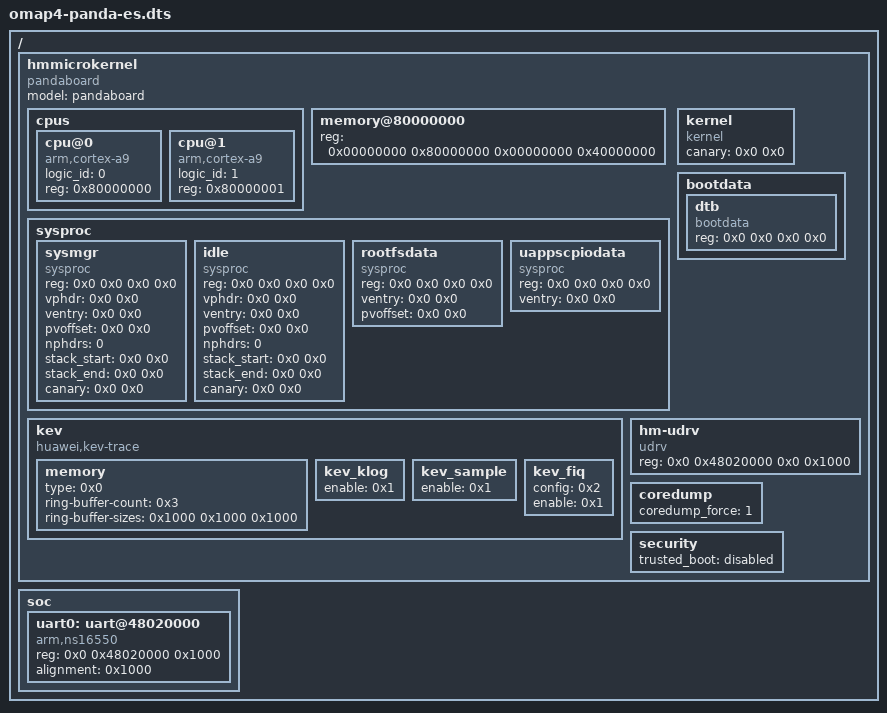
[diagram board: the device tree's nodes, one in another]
/dts-v1/;

/ { #address-cells = <2>; #size-cells = <2>; hmmicrokernel {
	model = "pandaboard";
	compatible = "pandaboard", "ti,omap4430";
	#address-cells = <2>;
	#size-cells = <2>;

	cpus {
		#address-cells = <1>;
		#size-cells = <0>;

		cpu@0 {
			compatible = "arm,cortex-a9";
			device_type = "cpu";
			logic_id = <0>;
			reg = <0x80000000>;
		};
		cpu@1 {
			compatible = "arm,cortex-a9";
			device_type = "cpu";
			logic_id = <1>;
			reg = <0x80000001>;
		};
	};

	memory@80000000 {
		device_type = "memory";
		reg = <0x00000000 0x80000000 0x00000000 0x40000000>;
	};

	sysproc {
		#address-cells = <2>;
		#size-cells = <2>;
		sysmgr {
			compatible = "sysproc", "sysmgr";
			/* filled by bootloader */
			reg      = <0x0 0x0 0x0 0x0>;
			vphdr    = <0x0 0x0>;
			ventry   = <0x0 0x0>;
			pvoffset = <0x0 0x0>;
			nphdrs   = <0>;
			stack_start = <0x0 0x0>;
			stack_end = <0x0 0x0>;
			canary = <0x0 0x0>;
		};
		idle {
			compatible = "sysproc", "idle";
			/* filled by bootloader */
			reg      = <0x0 0x0 0x0 0x0>;
			vphdr    = <0x0 0x0>;
			ventry   = <0x0 0x0>;
			pvoffset = <0x0 0x0>;
			nphdrs   = <0>;
			stack_start = <0x0 0x0>;
			stack_end = <0x0 0x0>;
			canary = <0x0 0x0>;
		};
		rootfsdata {
			compatible = "sysproc", "rootfs";
			/* filled by bootloader */
			reg      = <0x0 0x0 0x0 0x0>;
			ventry   = <0x0 0x0>;
			pvoffset = <0x0 0x0>;
		};
		uappscpiodata {
			compatible = "sysproc", "uappscpio";
			/* filled by bootloader */
			reg      = <0x0 0x0 0x0 0x0>;
			ventry   = <0x0 0x0>;
		};
	};

	kernel {
		compatible = "kernel";
		/* filled by bootloader */
		canary = <0x0 0x0>;
	};

	bootdata {
		#address-cells = <2>;
		#size-cells = <2>;
		dtb {
			compatible = "bootdata", "dtb";
			/* filled by bootloader */
			reg = <0x0 0x0 0x0 0x0>;
		};
	};

	kev {
		compatible = "huawei,kev-trace";

		memory {
			type = <0x0>;
			ring-buffer-count = <0x3>;
			ring-buffer-sizes = <0x1000 0x1000 0x1000>;
		};
		kev_klog {
			enable = <0x1>;
		};
		kev_sample {
			enable = <0x1>;
		};
		kev_fiq {
			config = <0x2>;
			enable = <0x1>;
		};
	};

	hm-udrv {
		compatible = "udrv";
		reg = <0x0 0x48020000 0x0 0x1000>;
	};

	coredump {
		coredump_force = <1>;
	};
	security {
		trusted_boot = "disabled";
	};
	};

	soc {
		#address-cells = <2>;
		#size-cells = <1>;
		uart0: uart@48020000 {
			compatible = "arm,ns16550", "arm,pl011,uart";
			reg = <0x0 0x48020000 0x1000>;
			alignment = <0x1000>;
		};
	};
};
